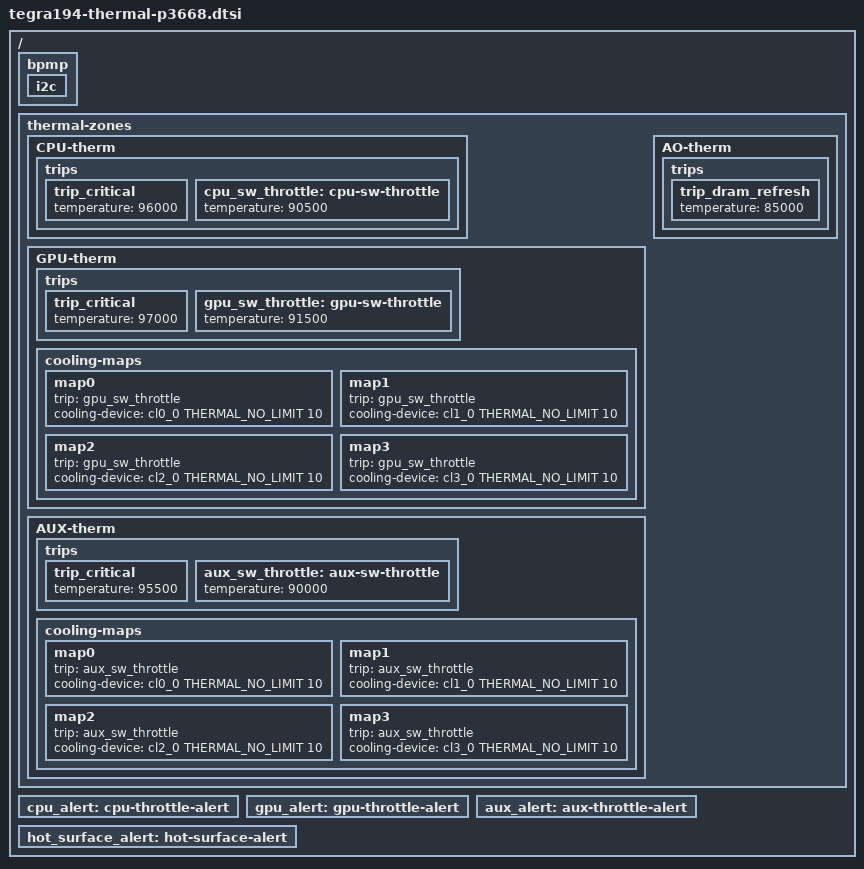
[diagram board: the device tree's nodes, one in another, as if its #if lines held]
/*
 * Copyright (c) 2019-2023, NVIDIA CORPORATION.  All rights reserved.
 *
 * This program is free software; you can redistribute it and/or modify
 * it under the terms of the GNU General Public License as published by
 * the Free Software Foundation; version 2 of the License.
 *
 * This program is distributed in the hope that it will be useful, but WITHOUT
 * ANY WARRANTY; without even the implied warranty of MERCHANTABILITY or
 * FITNESS FOR A PARTICULAR PURPOSE.  See the GNU General Public License for
 * more details.
 */

#include <t19x-common-platforms/tegra194-thermal.dtsi>
#include <t19x-common-platforms/tegra194-thermal-userspace-alert.dtsi>
/ {
#if TEGRA_BPMP_FW_DT_VERSION >= DT_VERSION_2
	bpmp { i2c {
#else
	bpmp_i2c {
#endif
		/delete-node/ temp-sensor@4c;
#if TEGRA_BPMP_FW_DT_VERSION >= DT_VERSION_2
	};
	};
#else
	};
#endif
	thermal-zones {
		/delete-node/ Tboard_tegra;
		/delete-node/ Tdiode_tegra;
		CPU-therm {
			trips {
				trip_critical {
					temperature = <96000>;
				};
				cpu_sw_throttle: cpu-sw-throttle {
					temperature = <90500>;
				};
			};
		};
		GPU-therm {
			trips {
				trip_critical {
					temperature = <97000>;
				};
				gpu_sw_throttle: gpu-sw-throttle {
					temperature = <91500>;
				};
			};
			cooling-maps {
				map0 {
					trip = <&gpu_sw_throttle>;
					cooling-device = <&cl0_0 THERMAL_NO_LIMIT 10>;
				};
				map1 {
					trip = <&gpu_sw_throttle>;
					cooling-device = <&cl1_0 THERMAL_NO_LIMIT 10>;
				};
				map2 {
					trip = <&gpu_sw_throttle>;
					cooling-device = <&cl2_0 THERMAL_NO_LIMIT 10>;
				};
				map3 {
					trip = <&gpu_sw_throttle>;
					cooling-device = <&cl3_0 THERMAL_NO_LIMIT 10>;
				};
			};
		};
		AUX-therm {
			trips {
				trip_critical {
					temperature = <95500>;
				};
				aux_sw_throttle: aux-sw-throttle {
					temperature = <90000>;
				};
			};
			cooling-maps {
				map0 {
					trip = <&aux_sw_throttle>;
					cooling-device = <&cl0_0 THERMAL_NO_LIMIT 10>;
				};
				map1 {
					trip = <&aux_sw_throttle>;
					cooling-device = <&cl1_0 THERMAL_NO_LIMIT 10>;
				};
				map2 {
					trip = <&aux_sw_throttle>;
					cooling-device = <&cl2_0 THERMAL_NO_LIMIT 10>;
				};
				map3 {
					trip = <&aux_sw_throttle>;
					cooling-device = <&cl3_0 THERMAL_NO_LIMIT 10>;
				};
			};
		};
		AO-therm {
			trips {
				trip_dram_refresh {
					temperature = <85000>;
				};
			};
		};
	};

	cpu_alert: cpu-throttle-alert {
		status = "okay";
	};

	gpu_alert: gpu-throttle-alert {
		status = "okay";
	};

	aux_alert: aux-throttle-alert {
		status = "okay";
	};

	hot_surface_alert: hot-surface-alert {
		status = "okay";
	};
};
